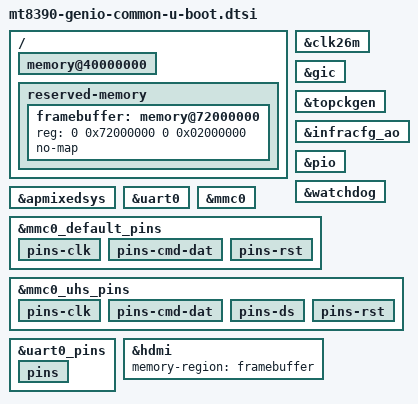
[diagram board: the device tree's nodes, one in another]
// SPDX-License-Identifier: (GPL-2.0 OR MIT)
/*
 * Copyright (c) 2026 BayLibre, SAS.
 * Author: Julien Stephan <jstephan@baylibre.com>
 * Author: Carlo Caione <ccaione@baylibre.com>
 */

&clk26m {
	bootph-pre-ram;
};

&gic {
	bootph-pre-ram;
};

&topckgen {
	bootph-pre-ram;
};

&infracfg_ao {
	bootph-pre-ram;
};

&pio {
	bootph-pre-ram;
};

&watchdog {
	bootph-pre-ram;
};

&apmixedsys {
	bootph-pre-ram;
};

&uart0 {
	bootph-pre-ram;
};

&mmc0 {
	bootph-pre-ram;
};

/ {
	memory@40000000 {
		bootph-pre-ram;
	};
};

&mmc0_default_pins {
	bootph-pre-ram;

	pins-clk {
		bootph-pre-ram;
	};

	pins-cmd-dat {
		bootph-pre-ram;
	};

	pins-rst {
		bootph-pre-ram;
	};
};

&mmc0_uhs_pins {
	bootph-pre-ram;

	pins-clk {
		bootph-pre-ram;
	};

	pins-cmd-dat {
		bootph-pre-ram;
	};

	pins-ds {
		bootph-pre-ram;
	};

	pins-rst {
		bootph-pre-ram;
	};
};

&uart0_pins {
	bootph-pre-ram;

	pins {
		bootph-pre-ram;
	};
};

/ {
	reserved-memory {
		/*
		 * Keep this region clear of the board reserved-memory
		 * pools (the boards using this SoC reserve regions up to
		 * 0x61100000 for the adsp/afe DMA pools) and of the kernel
		 * load window: the kernel FIT images load and decompress
		 * the kernel at 0x64000000.
		 */
		framebuffer: memory@72000000 {
			reg = <0 0x72000000 0 0x02000000>;
			no-map;
		};
	};
};

&hdmi {
	/* U-Boot specific: the framebuffer lives in this reserved region */
	memory-region = <&framebuffer>;
};
